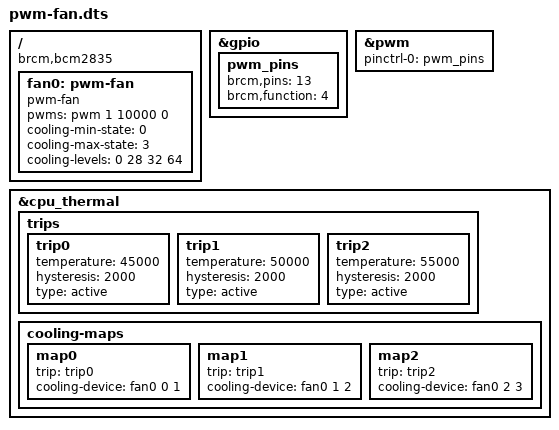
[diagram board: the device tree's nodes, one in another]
/dts-v1/;
/plugin/;

/*
PWM fan
*/

/ {
        compatible = "brcm,bcm2835";

        fragment@0 {
                target = <&gpio>;
                __overlay__ {
                        pwm_pins: pwm_pins {
                                brcm,pins = <13>;
                                brcm,function = <4>;
                        };
                };
        };

        fragment@1 {
                target = <&pwm>;
                __overlay__ {
                        pinctrl-names = "default";
                        pinctrl-0 = <&pwm_pins>;
                        status = "okay";
                };
        };

        fragment@2 {
                target-path = "/";
                __overlay__ {
			fan0: pwm-fan {
				compatible = "pwm-fan";
				pwms = <&pwm 1 10000 0>;
			        cooling-min-state = <0>;
				cooling-max-state = <3>;
				#cooling-cells = <2>;
				cooling-levels = <0 28 32 64>;
			};
                };
        };

 	fragment@3 {
 	target = <&cpu_thermal>;
        polling-delay = <2000>; /* milliseconds */
 		__overlay__ {
 			trips {
 				trip0: trip0 {
 					temperature = <45000>;
 					hysteresis = <2000>;
 					type = "active";
 				};
 				trip1: trip1 {
 					 temperature = <50000>;
 					 hysteresis = <2000>;
 					 type = "active";
 				};
 				trip2: trip2 {
 					 temperature = <55000>;
 					 hysteresis = <2000>;
 					 type = "active";
 				};
 			};
 			cooling-maps {
 				map0 {
 					trip = <&trip0>;
 					cooling-device = <&fan0 0 1>;
 				};
 				map1 {
 					 trip = <&trip1>;
 					 cooling-device = <&fan0 1 2>;
 				};
 				map2 {
 					 trip = <&trip2>;
 					 cooling-device = <&fan0 2 3>;
 				};
 			};
 		};
	};

        __overrides__ {
		pwm_pin   = <&pwm_pins>,"brcm,pins:0";
                pwm_fan_temp0 = <&trip0>,"temperature:0";
		pwm_fan_temp0_hyst = <&trip0>,"hysteresis:0";
                pwm_fan_temp1 = <&trip1>,"temperature:0";
		pwm_fan_temp1_hyst = <&trip1>,"hysteresis:0";
                pwm_fan_temp2 = <&trip2>,"temperature:0";
		pwm_fan_temp2_hyst = <&trip2>,"hysteresis:0";
        };

};
